AUTOSAR XML (schema 00046)
package /ComponentTypes
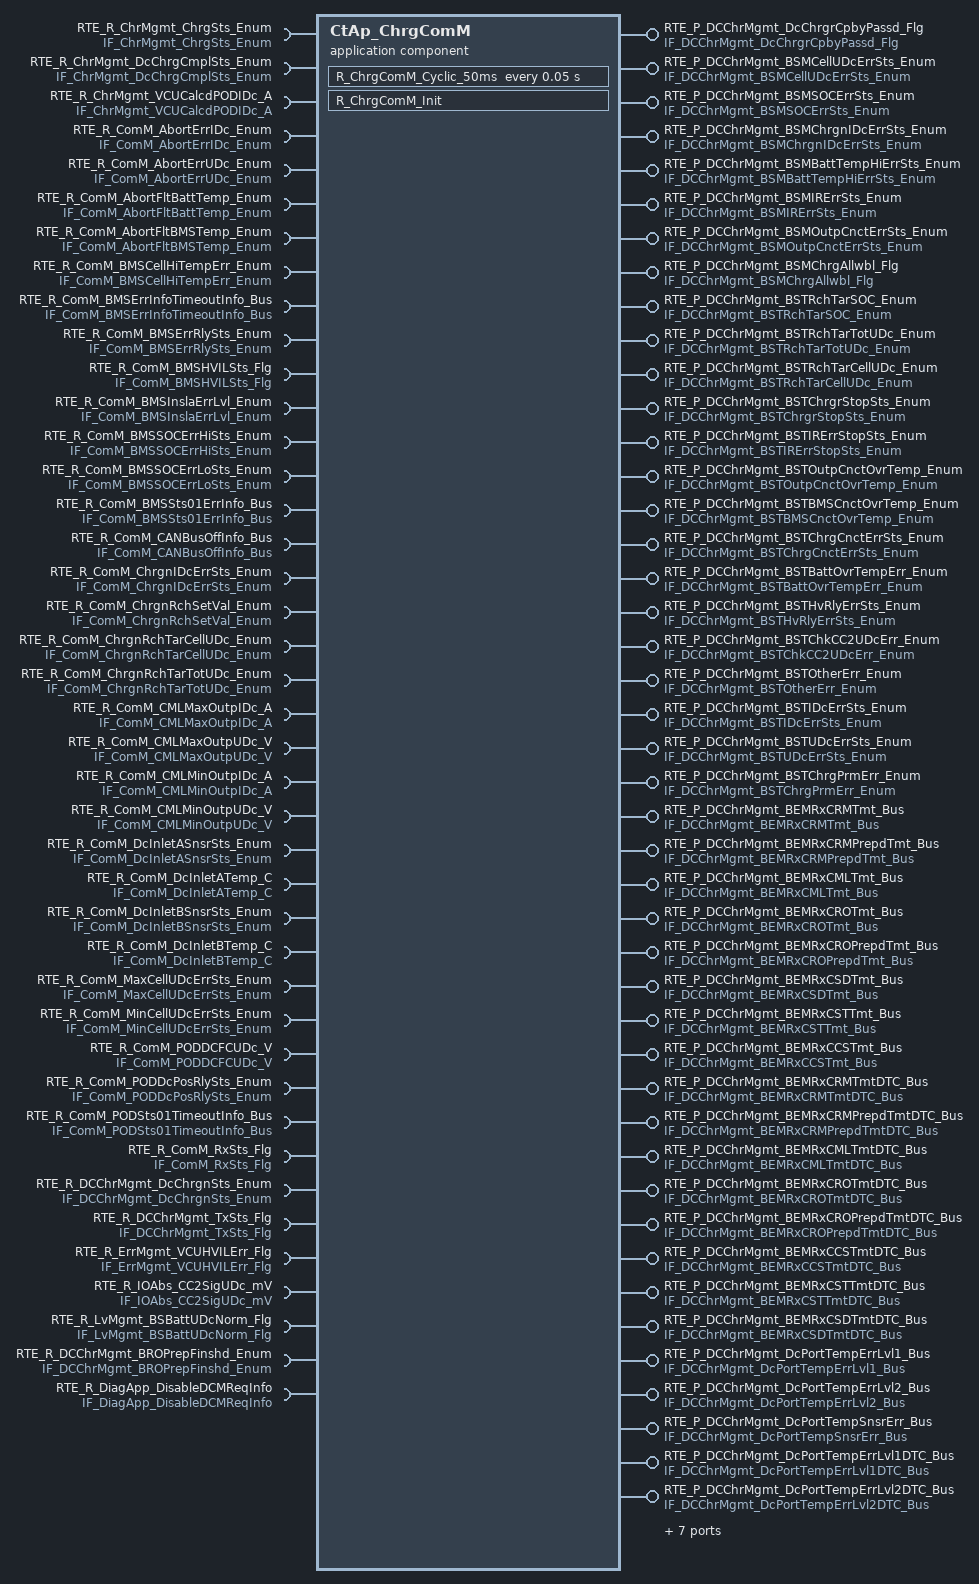
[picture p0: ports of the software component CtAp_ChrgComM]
  application sw component type CtAp_ChrgComM
    50 x provide port:
      RTE_P_DCChrMgmt_DcChrgrCpbyPassd_Flg: nonqueued-sender-com-spec{data-element=tec_DCChrMgmt_DcChrgrCpbyPassd_Flg, init-value=0}, provided-interface=IF_DCChrMgmt_DcChrgrCpbyPassd_Flg
      RTE_P_DCChrMgmt_BSMCellUDcErrSts_Enum: nonqueued-sender-com-spec{data-element=tec_DCChrMgmt_BSMCellUDcErrSts_Enum, init-value=0}, provided-interface=IF_DCChrMgmt_BSMCellUDcErrSts_Enum
      RTE_P_DCChrMgmt_BSMSOCErrSts_Enum: nonqueued-sender-com-spec{data-element=tec_DCChrMgmt_BSMSOCErrSts_Enum, init-value=0}, provided-interface=IF_DCChrMgmt_BSMSOCErrSts_Enum
      RTE_P_DCChrMgmt_BSMChrgnIDcErrSts_Enum: nonqueued-sender-com-spec{data-element=tec_DCChrMgmt_BSMChrgnIDcErrSts_Enum, init-value=0}, provided-interface=IF_DCChrMgmt_BSMChrgnIDcErrSts_Enum
      RTE_P_DCChrMgmt_BSMBattTempHiErrSts_Enum: nonqueued-sender-com-spec{data-element=tec_DCChrMgmt_BSMBattTempHiErrSts_Enum, init-value=0}, provided-interface=IF_DCChrMgmt_BSMBattTempHiErrSts_Enum
      RTE_P_DCChrMgmt_BSMIRErrSts_Enum: nonqueued-sender-com-spec{data-element=tec_DCChrMgmt_BSMIRErrSts_Enum, init-value=0}, provided-interface=IF_DCChrMgmt_BSMIRErrSts_Enum
      RTE_P_DCChrMgmt_BSMOutpCnctErrSts_Enum: nonqueued-sender-com-spec{data-element=tec_DCChrMgmt_BSMOutpCnctErrSts_Enum, init-value=0}, provided-interface=IF_DCChrMgmt_BSMOutpCnctErrSts_Enum
      RTE_P_DCChrMgmt_BSMChrgAllwbl_Flg: nonqueued-sender-com-spec{data-element=tec_DCChrMgmt_BSMChrgAllwbl_Flg, init-value=0}, provided-interface=IF_DCChrMgmt_BSMChrgAllwbl_Flg
      RTE_P_DCChrMgmt_BSTRchTarSOC_Enum: nonqueued-sender-com-spec{data-element=tec_DCChrMgmt_BSTRchTarSOC_Enum, init-value=0}, provided-interface=IF_DCChrMgmt_BSTRchTarSOC_Enum
      RTE_P_DCChrMgmt_BSTRchTarTotUDc_Enum: nonqueued-sender-com-spec{data-element=tec_DCChrMgmt_BSTRchTarTotUDc_Enum, init-value=0}, provided-interface=IF_DCChrMgmt_BSTRchTarTotUDc_Enum
      RTE_P_DCChrMgmt_BSTRchTarCellUDc_Enum: nonqueued-sender-com-spec{data-element=tec_DCChrMgmt_BSTRchTarCellUDc_Enum, init-value=0}, provided-interface=IF_DCChrMgmt_BSTRchTarCellUDc_Enum
      RTE_P_DCChrMgmt_BSTChrgrStopSts_Enum: nonqueued-sender-com-spec{data-element=tec_DCChrMgmt_BSTChrgrStopSts_Enum, init-value=0}, provided-interface=IF_DCChrMgmt_BSTChrgrStopSts_Enum
      RTE_P_DCChrMgmt_BSTIRErrStopSts_Enum: nonqueued-sender-com-spec{data-element=tec_DCChrMgmt_BSTIRErrStopSts_Enum, init-value=0}, provided-interface=IF_DCChrMgmt_BSTIRErrStopSts_Enum
      RTE_P_DCChrMgmt_BSTOutpCnctOvrTemp_Enum: nonqueued-sender-com-spec{data-element=tec_DCChrMgmt_BSTOutpCnctOvrTemp_Enum, init-value=0}, provided-interface=IF_DCChrMgmt_BSTOutpCnctOvrTemp_Enum
      RTE_P_DCChrMgmt_BSTBMSCnctOvrTemp_Enum: nonqueued-sender-com-spec{data-element=tec_DCChrMgmt_BSTBMSCnctOvrTemp_Enum, init-value=0}, provided-interface=IF_DCChrMgmt_BSTBMSCnctOvrTemp_Enum
      RTE_P_DCChrMgmt_BSTChrgCnctErrSts_Enum: nonqueued-sender-com-spec{data-element=tec_DCChrMgmt_BSTChrgCnctErrSts_Enum, init-value=0}, provided-interface=IF_DCChrMgmt_BSTChrgCnctErrSts_Enum
      RTE_P_DCChrMgmt_BSTBattOvrTempErr_Enum: nonqueued-sender-com-spec{data-element=tec_DCChrMgmt_BSTBattOvrTempErr_Enum, init-value=0}, provided-interface=IF_DCChrMgmt_BSTBattOvrTempErr_Enum
      RTE_P_DCChrMgmt_BSTHvRlyErrSts_Enum: nonqueued-sender-com-spec{data-element=tec_DCChrMgmt_BSTHvRlyErrSts_Enum, init-value=0}, provided-interface=IF_DCChrMgmt_BSTHvRlyErrSts_Enum
      RTE_P_DCChrMgmt_BSTChkCC2UDcErr_Enum: nonqueued-sender-com-spec{data-element=tec_DCChrMgmt_BSTChkCC2UDcErr_Enum, init-value=0}, provided-interface=IF_DCChrMgmt_BSTChkCC2UDcErr_Enum
      RTE_P_DCChrMgmt_BSTOtherErr_Enum: nonqueued-sender-com-spec{data-element=tec_DCChrMgmt_BSTOtherErr_Enum, init-value=0}, provided-interface=IF_DCChrMgmt_BSTOtherErr_Enum
      RTE_P_DCChrMgmt_BSTIDcErrSts_Enum: nonqueued-sender-com-spec{data-element=tec_DCChrMgmt_BSTIDcErrSts_Enum, init-value=0}, provided-interface=IF_DCChrMgmt_BSTIDcErrSts_Enum
      RTE_P_DCChrMgmt_BSTUDcErrSts_Enum: nonqueued-sender-com-spec{data-element=tec_DCChrMgmt_BSTUDcErrSts_Enum, init-value=0}, provided-interface=IF_DCChrMgmt_BSTUDcErrSts_Enum
      RTE_P_DCChrMgmt_BSTChrgPrmErr_Enum: nonqueued-sender-com-spec{data-element=tec_DCChrMgmt_BSTChrgPrmErr_Enum, init-value=0}, provided-interface=IF_DCChrMgmt_BSTChrgPrmErr_Enum
      RTE_P_DCChrMgmt_BEMRxCRMTmt_Bus: nonqueued-sender-com-spec{data-element=tec_DCChrMgmt_BEMRxCRMTmt_Bus, init-value=fields=[DCChrMgmt_MonStatBEMRxCRMTmt:0, DCChrMgmt_MonResBEMRxCRMTmt:0, DCChrMgmt_ErrStatBEMRxCRMTmt:0, DCChrMgmt_ErrResBEMRxCRMTmt:0]}, provided-interface=IF_DCChrMgmt_BEMRxCRMTmt_Bus
      RTE_P_DCChrMgmt_BEMRxCRMPrepdTmt_Bus: nonqueued-sender-com-spec{data-element=tec_DCChrMgmt_BEMRxCRMPrepdTmt_Bus, init-value=fields=[DCChrMgmt_MonStatBEMRxCRMPrepdTmt:0, DCChrMgmt_MonResBEMRxCRMPrepdTmt:0, DCChrMgmt_ErrStatBEMRxCRMPrepdTmt:0, DCChrMgmt_ErrResBEMRxCRMPrepdTmt:0]}, provided-interface=IF_DCChrMgmt_BEMRxCRMPrepdTmt_Bus
      RTE_P_DCChrMgmt_BEMRxCMLTmt_Bus: nonqueued-sender-com-spec{data-element=tec_DCChrMgmt_BEMRxCMLTmt_Bus, init-value=fields=[DCChrMgmt_MonStatBEMRxCMLTmt:0, DCChrMgmt_MonResBEMRxCMLTmt:0, DCChrMgmt_ErrStatBEMRxCMLTmt:0, DCChrMgmt_ErrResBEMRxCMLTmt:0]}, provided-interface=IF_DCChrMgmt_BEMRxCMLTmt_Bus
      RTE_P_DCChrMgmt_BEMRxCROTmt_Bus: nonqueued-sender-com-spec{data-element=tec_DCChrMgmt_BEMRxCROTmt_Bus, init-value=fields=[DCChrMgmt_MonStatBEMRxCROTmt:0, DCChrMgmt_MonResBEMRxCROTmt:0, DCChrMgmt_ErrStatBEMRxCROTmt:0, DCChrMgmt_ErrResBEMRxCROTmt:0]}, provided-interface=IF_DCChrMgmt_BEMRxCROTmt_Bus
      RTE_P_DCChrMgmt_BEMRxCROPrepdTmt_Bus: nonqueued-sender-com-spec{data-element=tec_DCChrMgmt_BEMRxCROPrepdTmt_Bus, init-value=fields=[DCChrMgmt_MonStatBEMRxCROPrepdTmt:0, DCChrMgmt_MonResBEMRxCROPrepdTmt:0, DCChrMgmt_ErrStatBEMRxCROPrepdTmt:0, DCChrMgmt_ErrResBEMRxCROPrepdTmt:0]}, provided-interface=IF_DCChrMgmt_BEMRxCROPrepdTmt_Bus
      RTE_P_DCChrMgmt_BEMRxCSDTmt_Bus: nonqueued-sender-com-spec{data-element=tec_DCChrMgmt_BEMRxCSDTmt_Bus, init-value=fields=[DCChrMgmt_MonStatBEMRxCSDTmt:0, DCChrMgmt_MonResBEMRxCSDTmt:0, DCChrMgmt_ErrStatBEMRxCSDTmt:0, DCChrMgmt_ErrResBEMRxCSDTmt:0]}, provided-interface=IF_DCChrMgmt_BEMRxCSDTmt_Bus
      RTE_P_DCChrMgmt_BEMRxCSTTmt_Bus: nonqueued-sender-com-spec{data-element=tec_DCChrMgmt_BEMRxCSTTmt_Bus, init-value=fields=[DCChrMgmt_MonStatBEMRxCSTTmt:0, DCChrMgmt_MonResBEMRxCSTTmt:0, DCChrMgmt_ErrStatBEMRxCSTTmt:0, DCChrMgmt_ErrResBEMRxCSTTmt:0]}, provided-interface=IF_DCChrMgmt_BEMRxCSTTmt_Bus
      RTE_P_DCChrMgmt_BEMRxCCSTmt_Bus: nonqueued-sender-com-spec{data-element=tec_DCChrMgmt_BEMRxCCSTmt_Bus, init-value=fields=[DCChrMgmt_MonStatBEMRxCCSTmt:0, DCChrMgmt_MonResBEMRxCCSTmt:0, DCChrMgmt_ErrStatBEMRxCCSTmt:0, DCChrMgmt_ErrResBEMRxCCSTmt:0]}, provided-interface=IF_DCChrMgmt_BEMRxCCSTmt_Bus
      RTE_P_DCChrMgmt_BEMRxCRMTmtDTC_Bus: nonqueued-sender-com-spec{data-element=tec_DCChrMgmt_BEMRxCRMTmtDTC_Bus, init-value=fields=[DCChrMgmt_MonStatBEMRxCRMTmtDTC:0, DCChrMgmt_MonResBEMRxCRMTmtDTC:0, DCChrMgmt_ErrStatBEMRxCRMTmtDTC:0, DCChrMgmt_ErrResBEMRxCRMTmtDTC:0]}, provided-interface=IF_DCChrMgmt_BEMRxCRMTmtDTC_Bus
      RTE_P_DCChrMgmt_BEMRxCRMPrepdTmtDTC_Bus: nonqueued-sender-com-spec{data-element=tec_DCChrMgmt_BEMRxCRMPrepdTmtDTC_Bus, init-value=fields=[DCChrMgmt_MonStatBEMRxCRMPrepdTmtDTC:0, DCChrMgmt_MonResBEMRxCRMPrepdTmtDTC:0, DCChrMgmt_ErrStatBEMRxCRMPrepdTmtDTC:0, DCChrMgmt_ErrResBEMRxCRMPrepdTmtDTC:0]}, provided-interface=IF_DCChrMgmt_BEMRxCRMPrepdTmtDTC_Bus
      RTE_P_DCChrMgmt_BEMRxCMLTmtDTC_Bus: nonqueued-sender-com-spec{data-element=tec_DCChrMgmt_BEMRxCMLTmtDTC_Bus, init-value=fields=[DCChrMgmt_MonStatBEMRxCMLTmtDTC:0, DCChrMgmt_MonResBEMRxCMLTmtDTC:0, DCChrMgmt_ErrStatBEMRxCMLTmtDTC:0, DCChrMgmt_ErrResBEMRxCMLTmtDTC:0]}, provided-interface=IF_DCChrMgmt_BEMRxCMLTmtDTC_Bus
      RTE_P_DCChrMgmt_BEMRxCROTmtDTC_Bus: nonqueued-sender-com-spec{data-element=tec_DCChrMgmt_BEMRxCROTmtDTC_Bus, init-value=fields=[DCChrMgmt_MonStatBEMRxCROTmtDTC:0, DCChrMgmt_MonResBEMRxCROTmtDTC:0, DCChrMgmt_ErrStatBEMRxCROTmtDTC:0, DCChrMgmt_ErrResBEMRxCROTmtDTC:0]}, provided-interface=IF_DCChrMgmt_BEMRxCROTmtDTC_Bus
      RTE_P_DCChrMgmt_BEMRxCROPrepdTmtDTC_Bus: nonqueued-sender-com-spec{data-element=tec_DCChrMgmt_BEMRxCROPrepdTmtDTC_Bus, init-value=fields=[DCChrMgmt_MonStatBEMRxCROPrepdTmtDTC:0, DCChrMgmt_MonResBEMRxCROPrepdTmtDTC:0, DCChrMgmt_ErrStatBEMRxCROPrepdTmtDTC:0, DCChrMgmt_ErrResBEMRxCROPrepdTmtDTC:0]}, provided-interface=IF_DCChrMgmt_BEMRxCROPrepdTmtDTC_Bus
      RTE_P_DCChrMgmt_BEMRxCCSTmtDTC_Bus: nonqueued-sender-com-spec{data-element=tec_DCChrMgmt_BEMRxCCSTmtDTC_Bus, init-value=fields=[DCChrMgmt_MonStatBEMRxCCSTmtDTC:0, DCChrMgmt_MonResBEMRxCCSTmtDTC:0, DCChrMgmt_ErrStatBEMRxCCSTmtDTC:0, DCChrMgmt_ErrResBEMRxCCSTmtDTC:0]}, provided-interface=IF_DCChrMgmt_BEMRxCCSTmtDTC_Bus
      RTE_P_DCChrMgmt_BEMRxCSTTmtDTC_Bus: nonqueued-sender-com-spec{data-element=tec_DCChrMgmt_BEMRxCSTTmtDTC_Bus, init-value=fields=[DCChrMgmt_MonStatBEMRxCSTTmtDTC:0, DCChrMgmt_MonResBEMRxCSTTmtDTC:0, DCChrMgmt_ErrStatBEMRxCSTTmtDTC:0, DCChrMgmt_ErrResBEMRxCSTTmtDTC:0]}, provided-interface=IF_DCChrMgmt_BEMRxCSTTmtDTC_Bus
      RTE_P_DCChrMgmt_BEMRxCSDTmtDTC_Bus: nonqueued-sender-com-spec{data-element=tec_DCChrMgmt_BEMRxCSDTmtDTC_Bus, init-value=fields=[DCChrMgmt_MonStatBEMRxCSDTmtDTC:0, DCChrMgmt_MonResBEMRxCSDTmtDTC:0, DCChrMgmt_ErrStatBEMRxCSDTmtDTC:0, DCChrMgmt_ErrResBEMRxCSDTmtDTC:0]}, provided-interface=IF_DCChrMgmt_BEMRxCSDTmtDTC_Bus
      RTE_P_DCChrMgmt_DcPortTempErrLvl1_Bus: nonqueued-sender-com-spec{data-element=tec_DCChrMgmt_DcPortTempErrLvl1_Bus, init-value=fields=[DCChrMgmt_MonStatDcPortTempErrLvl1:0, DCChrMgmt_MonResDcPortTempErrLvl1:0, DCChrMgmt_ErrStatDcPortTempErrLvl1:0, DCChrMgmt_ErrResDcPortTempErrLvl1:0]}, provided-interface=IF_DCChrMgmt_DcPortTempErrLvl1_Bus
      RTE_P_DCChrMgmt_DcPortTempErrLvl2_Bus: nonqueued-sender-com-spec{data-element=tec_DCChrMgmt_DcPortTempErrLvl2_Bus, init-value=fields=[DCChrMgmt_MonStatDcPortTempErrLvl2:0, DCChrMgmt_MonResDcPortTempErrLvl2:0, DCChrMgmt_ErrStatDcPortTempErrLvl2:0, DCChrMgmt_ErrResDcPortTempErrLvl2:0]}, provided-interface=IF_DCChrMgmt_DcPortTempErrLvl2_Bus
      RTE_P_DCChrMgmt_DcPortTempSnsrErr_Bus: nonqueued-sender-com-spec{data-element=tec_DCChrMgmt_DcPortTempSnsrErr_Bus, init-value=fields=[DCChrMgmt_MonStatDcPortTempSnsrErr:0, DCChrMgmt_MonResDcPortTempSnsrErr:0, DCChrMgmt_ErrStatDcPortTempSnsrErr:0, DCChrMgmt_ErrResDcPortTempSnsrErr:0]}, provided-interface=IF_DCChrMgmt_DcPortTempSnsrErr_Bus
      RTE_P_DCChrMgmt_DcPortTempErrLvl1DTC_Bus: nonqueued-sender-com-spec{data-element=tec_DCChrMgmt_DcPortTempErrLvl1DTC_Bus, init-value=fields=[DCChrMgmt_MonStatDcPortTempErrLvl1DTC:0, DCChrMgmt_MonResDcPortTempErrLvl1DTC:0, DCChrMgmt_ErrStatDcPortTempErrLvl1DTC:0, DCChrMgmt_ErrResDcPortTempErrLvl1DTC:0]}, provided-interface=IF_DCChrMgmt_DcPortTempErrLvl1DTC_Bus
      RTE_P_DCChrMgmt_DcPortTempErrLvl2DTC_Bus: nonqueued-sender-com-spec{data-element=tec_DCChrMgmt_DcPortTempErrLvl2DTC_Bus, init-value=fields=[DCChrMgmt_MonStatDcPortTempErrLvl2DTC:0, DCChrMgmt_MonResDcPortTempErrLvl2DTC:0, DCChrMgmt_ErrStatDcPortTempErrLvl2DTC:0, DCChrMgmt_ErrResDcPortTempErrLvl2DTC:0]}, provided-interface=IF_DCChrMgmt_DcPortTempErrLvl2DTC_Bus
      RTE_P_DCChrMgmt_DcPortTempSnsrErrDTC_Bus: nonqueued-sender-com-spec{data-element=tec_DCChrMgmt_DcPortTempSnsrErrDTC_Bus, init-value=fields=[DCChrMgmt_MonStatDcPortTempSnsrErrDTC:0, DCChrMgmt_MonResDcPortTempSnsrErrDTC:0, DCChrMgmt_ErrStatDcPortTempSnsrErrDTC:0, DCChrMgmt_ErrResDcPortTempSnsrErrDTC:0]}, provided-interface=IF_DCChrMgmt_DcPortTempSnsrErrDTC_Bus
      RTE_P_DCChrMgmt_MaxChrgUDc_V: nonqueued-sender-com-spec{data-element=tec_DCChrMgmt_MaxChrgUDc_V, init-value=0}, provided-interface=IF_DCChrMgmt_MaxChrgUDc_V
      RTE_P_DCChrMgmt_MinChrgUDc_V: nonqueued-sender-com-spec{data-element=tec_DCChrMgmt_MinChrgUDc_V, init-value=0}, provided-interface=IF_DCChrMgmt_MinChrgUDc_V
      RTE_P_DCChrMgmt_MaxChrgIDc_A: nonqueued-sender-com-spec{data-element=tec_DCChrMgmt_MaxChrgIDc_A, init-value=0}, provided-interface=IF_DCChrMgmt_MaxChrgIDc_A
      RTE_P_DCChrMgmt_MinChrgIDc_A: nonqueued-sender-com-spec{data-element=tec_DCChrMgmt_MinChrgIDc_A, init-value=0}, provided-interface=IF_DCChrMgmt_MinChrgIDc_A
      RTE_P_DCChrMgmt_BEMTxReqSts_Enum: nonqueued-sender-com-spec{data-element=tec_DCChrMgmt_BEMTxReqSts_Enum, init-value=0}, provided-interface=IF_DCChrMgmt_BEMTxReqSts_Enum
    41 x require port:
      RTE_R_ChrMgmt_ChrgSts_Enum: nonqueued-receiver-com-spec{data-element=tec_ChrMgmt_ChrgSts_Enum, filter=data-filter-type=ALWAYS, init-value=0}, required-interface=IF_ChrMgmt_ChrgSts_Enum
      RTE_R_ChrMgmt_DcChrgCmplSts_Enum: nonqueued-receiver-com-spec{data-element=tec_ChrMgmt_DcChrgCmplSts_Enum, filter=data-filter-type=ALWAYS, init-value=0}, required-interface=IF_ChrMgmt_DcChrgCmplSts_Enum
      RTE_R_ChrMgmt_VCUCalcdPODIDc_A: nonqueued-receiver-com-spec{data-element=tec_ChrMgmt_VCUCalcdPODIDc_A, filter=data-filter-type=ALWAYS, init-value=0}, required-interface=IF_ChrMgmt_VCUCalcdPODIDc_A
      RTE_R_ComM_AbortErrIDc_Enum: nonqueued-receiver-com-spec{data-element=tec_ComM_AbortErrIDc_Enum, filter=data-filter-type=ALWAYS, init-value=0}, required-interface=IF_ComM_AbortErrIDc_Enum
      RTE_R_ComM_AbortErrUDc_Enum: nonqueued-receiver-com-spec{data-element=tec_ComM_AbortErrUDc_Enum, filter=data-filter-type=ALWAYS, init-value=0}, required-interface=IF_ComM_AbortErrUDc_Enum
      RTE_R_ComM_AbortFltBattTemp_Enum: nonqueued-receiver-com-spec{data-element=tec_ComM_AbortFltBattTemp_Enum, filter=data-filter-type=ALWAYS, init-value=0}, required-interface=IF_ComM_AbortFltBattTemp_Enum
      RTE_R_ComM_AbortFltBMSTemp_Enum: nonqueued-receiver-com-spec{data-element=tec_ComM_AbortFltBMSTemp_Enum, filter=data-filter-type=ALWAYS, init-value=0}, required-interface=IF_ComM_AbortFltBMSTemp_Enum
      RTE_R_ComM_BMSCellHiTempErr_Enum: nonqueued-receiver-com-spec{data-element=tec_ComM_BMSCellHiTempErr_Enum, filter=data-filter-type=ALWAYS, init-value=0}, required-interface=IF_ComM_BMSCellHiTempErr_Enum
      RTE_R_ComM_BMSErrInfoTimeoutInfo_Bus: nonqueued-receiver-com-spec{data-element=tec_ComM_BMSErrInfoTimeoutInfo_Bus, filter=data-filter-type=ALWAYS, init-value=fields=[ComM_MonStatBMSErrInfoTimeoutInfo:0, ComM_MonResBMSErrInfoTimeoutInfo:0, ComM_ErrStatBMSErrInfoTimeoutInfo:0, ComM_ErrResBMSErrInfoTimeoutInfo:0]}, required-interface=IF_ComM_BMSErrInfoTimeoutInfo_Bus
      RTE_R_ComM_BMSErrRlySts_Enum: nonqueued-receiver-com-spec{data-element=tec_ComM_BMSErrRlySts_Enum, filter=data-filter-type=ALWAYS, init-value=0}, required-interface=IF_ComM_BMSErrRlySts_Enum
      RTE_R_ComM_BMSHVILSts_Flg: nonqueued-receiver-com-spec{data-element=tec_ComM_BMSHVILSts_Flg, filter=data-filter-type=ALWAYS, init-value=0}, required-interface=IF_ComM_BMSHVILSts_Flg
      RTE_R_ComM_BMSInslaErrLvl_Enum: nonqueued-receiver-com-spec{data-element=tec_ComM_BMSInslaErrLvl_Enum, filter=data-filter-type=ALWAYS, init-value=0}, required-interface=IF_ComM_BMSInslaErrLvl_Enum
      RTE_R_ComM_BMSSOCErrHiSts_Enum: nonqueued-receiver-com-spec{data-element=tec_ComM_BMSSOCHiErrSts_Enum, filter=data-filter-type=ALWAYS, init-value=0}, required-interface=IF_ComM_BMSSOCErrHiSts_Enum
      RTE_R_ComM_BMSSOCErrLoSts_Enum: nonqueued-receiver-com-spec{data-element=tec_ComM_BMSSOCLoErrSts_Enum, filter=data-filter-type=ALWAYS, init-value=0}, required-interface=IF_ComM_BMSSOCErrLoSts_Enum
      RTE_R_ComM_BMSSts01ErrInfo_Bus: required-interface=IF_ComM_BMSSts01ErrInfo_Bus
        required-com-specs:
          data-element=tec_ComM_BMSSts01TimeoutInfo_Bus, filter=data-filter-type=ALWAYS, init-value=fields=[ComM_MonStatBMSSts01TimeoutInfo:0, ComM_MonResBMSSts01TimeoutInfo:0, ComM_ErrStatBMSSts01TimeoutInfo:0, ComM_ErrResBMSSts01TimeoutInfo:0]
          data-element=tec_ComM_BMSSts01CRCDTCInfo_Bus, filter=data-filter-type=ALWAYS, init-value=fields=[ComM_MonStatBMSSts01CRCDTCErrorInfo:0, ComM_MonResBMSSts01CRCDTCErrorInfo:0, ComM_ErrStatBMSSts01CRCDTCErrorInfo:0, ComM_ErrResBMSSts01CRCDTCErrorInfo:0]
          data-element=tec_ComM_BMSSts01CRCInfo_Bus, filter=data-filter-type=ALWAYS, init-value=fields=[ComM_MonStatBMSSts01CRCErrorInfo:0, ComM_MonResBMSSts01CRCErrorInfo:0, ComM_ErrStatBMSSts01CRCErrorInfo:0, ComM_ErrResBMSSts01CRCErrorInfo:0]
          data-element=tec_ComM_BMSSts01TimeoutDTCInfo_Bus, filter=data-filter-type=ALWAYS, init-value=fields=[ComM_MonStatBMSSts01TimeoutDTCErrorInfo:0, ComM_MonResBMSSts01TimeoutDTCErrorInfo:0, ComM_ErrStatBMSSts01TimeoutDTCErrorInfo:0, ComM_ErrResBMSSts01TimeoutDTCErrorInfo:0]
          data-element=tec_ComM_BMSSts01E2ETimeoutInfo_Bus, filter=data-filter-type=ALWAYS, init-value=fields=[ComM_MonStatBMSSts01E2ETimeoutInfo:0, ComM_MonResBMSSts01E2ETimeoutInfo:0, ComM_ErrStatBMSSts01E2ETimeoutInfo:0, ComM_ErrResBMSSts01E2ETimeoutInfo:0]
      RTE_R_ComM_CANBusOffInfo_Bus: required-interface=IF_ComM_CANBusOffInfo_Bus
        required-com-specs:
          data-element=tec_ComM_EPTCANBusOffInfo_Bus, filter=data-filter-type=ALWAYS, init-value=fields=[ComM_MonStatEPTCANBusOffInfo:0, ComM_MonResEPTCANBusOffInfo:0, ComM_ErrStatEPTCANBusOffInfo:0, ComM_ErrResEPTCANBusOffInfo:0]
          data-element=tec_ComM_CHCANBusOffInfo_Bus, filter=data-filter-type=ALWAYS, init-value=fields=[ComM_MonStatCHCANBusOffInfo:0, ComM_MonResCHCANBusOffInfo:0, ComM_ErrStatCHCANBusOffInfo:0, ComM_ErrResCHCANBusOffInfo:0]
          data-element=tec_ComM_EPTCANBusOffDTCInfo_Bus, filter=data-filter-type=ALWAYS, init-value=fields=[ComM_MonStatEPTCANBusOffDTCInfo:0, ComM_MonResEPTCANBusOffDTCInfo:0, ComM_ErrStatEPTCANBusOffDTCInfo:0, ComM_ErrResEPTCANBusOffDTCInfo:0]
          data-element=tec_ComM_CHCANBusOffDTCInfo_Bus, filter=data-filter-type=ALWAYS, init-value=fields=[ComM_MonStatCHCANBusOffDTCInfo:0, ComM_MonResCHCANBusOffDTCInfo:0, ComM_ErrStatCHCANBusOffDTCInfo:0, ComM_ErrResCHCANBusOffDTCInfo:0]
          data-element=tec_ComM_DCCANBusOffDTCInfo_Bus, filter=data-filter-type=ALWAYS, init-value=fields=[ComM_MonStatDCCANDTCBusOffInfo:0, ComM_MonResDCCANDTCBusOffInfo:0, ComM_ErrStatDCCANDTCBusOffInfo:0, ComM_ErrResDCCANDTCBusOffInfo:0]
          data-element=tec_ComM_DCCANBusOffInfo_Bus, filter=data-filter-type=ALWAYS, init-value=fields=[ComM_MonStatDCCANBusOffInfo:0, ComM_MonResDCCANBusOffInfo:0, ComM_ErrStatDCCANBusOffInfo:0, ComM_ErrResDCCANBusOffInfo:0]
      RTE_R_ComM_ChrgnIDcErrSts_Enum: nonqueued-receiver-com-spec{data-element=tec_ComM_ChrgnIDcErrSts_Enum, filter=data-filter-type=ALWAYS, init-value=0}, required-interface=IF_ComM_ChrgnIDcErrSts_Enum
      RTE_R_ComM_ChrgnRchSetVal_Enum: nonqueued-receiver-com-spec{data-element=tec_ComM_ChrgnRchSetVal_Enum, filter=data-filter-type=ALWAYS, init-value=0}, required-interface=IF_ComM_ChrgnRchSetVal_Enum
      RTE_R_ComM_ChrgnRchTarCellUDc_Enum: nonqueued-receiver-com-spec{data-element=tec_ComM_ChrgnRchTarCellUDc_Enum, filter=data-filter-type=ALWAYS, init-value=0}, required-interface=IF_ComM_ChrgnRchTarCellUDc_Enum
      RTE_R_ComM_ChrgnRchTarTotUDc_Enum: nonqueued-receiver-com-spec{data-element=tec_ComM_ChrgnRchTarTotUDc_Enum, filter=data-filter-type=ALWAYS, init-value=0}, required-interface=IF_ComM_ChrgnRchTarTotUDc_Enum
      RTE_R_ComM_CMLMaxOutpIDc_A: nonqueued-receiver-com-spec{data-element=tec_ComM_CMLMaxOutpIDc_A, filter=data-filter-type=ALWAYS, init-value=0}, required-interface=IF_ComM_CMLMaxOutpIDc_A
      RTE_R_ComM_CMLMaxOutpUDc_V: nonqueued-receiver-com-spec{data-element=tec_ComM_CMLMaxOutpUDc_V, filter=data-filter-type=ALWAYS, init-value=0}, required-interface=IF_ComM_CMLMaxOutpUDc_V
      RTE_R_ComM_CMLMinOutpIDc_A: nonqueued-receiver-com-spec{data-element=tec_ComM_CMLMinOutpIDc_A, filter=data-filter-type=ALWAYS, init-value=0}, required-interface=IF_ComM_CMLMinOutpIDc_A
      RTE_R_ComM_CMLMinOutpUDc_V: nonqueued-receiver-com-spec{data-element=tec_ComM_CMLMinOutpUDc_V, filter=data-filter-type=ALWAYS, init-value=0}, required-interface=IF_ComM_CMLMinOutpUDc_V
      RTE_R_ComM_DcInletASnsrSts_Enum: nonqueued-receiver-com-spec{data-element=tec_ComM_DcInletASnsrSts_Enum, filter=data-filter-type=ALWAYS, init-value=0}, required-interface=IF_ComM_DcInletASnsrSts_Enum
      RTE_R_ComM_DcInletATemp_C: nonqueued-receiver-com-spec{data-element=tec_ComM_DcInletATemp_C, filter=data-filter-type=ALWAYS, init-value=0}, required-interface=IF_ComM_DcInletATemp_C
      RTE_R_ComM_DcInletBSnsrSts_Enum: nonqueued-receiver-com-spec{data-element=tec_ComM_DcInletBSnsrSts_Enum, filter=data-filter-type=ALWAYS, init-value=0}, required-interface=IF_ComM_DcInletBSnsrSts_Enum
      RTE_R_ComM_DcInletBTemp_C: nonqueued-receiver-com-spec{data-element=tec_ComM_DcInletBTemp_C, filter=data-filter-type=ALWAYS, init-value=0}, required-interface=IF_ComM_DcInletBTemp_C
      RTE_R_ComM_MaxCellUDcErrSts_Enum: nonqueued-receiver-com-spec{data-element=tec_ComM_MaxCellUDcErrSts_Enum, filter=data-filter-type=ALWAYS, init-value=0}, required-interface=IF_ComM_MaxCellUDcErrSts_Enum
      RTE_R_ComM_MinCellUDcErrSts_Enum: nonqueued-receiver-com-spec{data-element=tec_ComM_MinCellUDcErrSts_Enum, filter=data-filter-type=ALWAYS, init-value=0}, required-interface=IF_ComM_MinCellUDcErrSts_Enum
      RTE_R_ComM_PODDCFCUDc_V: nonqueued-receiver-com-spec{data-element=tec_ComM_PODDCFCUDc_V, filter=data-filter-type=ALWAYS, init-value=0}, required-interface=IF_ComM_PODDCFCUDc_V
      RTE_R_ComM_PODDcPosRlySts_Enum: nonqueued-receiver-com-spec{data-element=tec_ComM_PODDcPosRlySts_Enum, filter=data-filter-type=ALWAYS, init-value=0}, required-interface=IF_ComM_PODDcPosRlySts_Enum
      RTE_R_ComM_PODSts01TimeoutInfo_Bus: nonqueued-receiver-com-spec{data-element=tec_ComM_PODSts01TimeoutInfo_Bus, filter=data-filter-type=ALWAYS, init-value=fields=[ComM_MonStatPODSts01TimeoutInfo:0, ComM_MonResPODSts01TimeoutInfo:0, ComM_ErrStatPODSts01TimeoutInfo:0, ComM_ErrResPODSts01TimeoutInfo:0]}, required-interface=IF_ComM_PODSts01TimeoutInfo_Bus
      RTE_R_ComM_RxSts_Flg: required-interface=IF_ComM_RxSts_Flg
        required-com-specs:
          data-element=tec_ComM_RxCROSts_Flg, filter=data-filter-type=ALWAYS, init-value=0
          data-element=tec_ComM_RxCEMSts_Flg, filter=data-filter-type=ALWAYS, init-value=0
          data-element=tec_ComM_RxCHMSts_Flg, filter=data-filter-type=ALWAYS, init-value=0
          data-element=tec_ComM_RxCSTSts_Flg, filter=data-filter-type=ALWAYS, init-value=0
          data-element=tec_ComM_RxCSDSts_Flg, filter=data-filter-type=ALWAYS, init-value=0
          data-element=tec_ComM_RxCCSSts_Flg, filter=data-filter-type=ALWAYS, init-value=0
          data-element=tec_ComM_RxCMLSts_Flg, filter=data-filter-type=ALWAYS, init-value=0
          data-element=tec_ComM_RxCRMSts_Flg, filter=data-filter-type=ALWAYS, init-value=0
      RTE_R_DCChrMgmt_DcChrgnSts_Enum: nonqueued-receiver-com-spec{data-element=tec_DCChrMgmt_DcChrgnSts_Enum, filter=data-filter-type=ALWAYS, init-value=0}, required-interface=IF_DCChrMgmt_DcChrgnSts_Enum
      RTE_R_DCChrMgmt_TxSts_Flg: required-interface=IF_DCChrMgmt_TxSts_Flg
        required-com-specs:
          data-element=tec_DCChrMgmt_TxBSDSts_Flg, filter=data-filter-type=ALWAYS, init-value=0
          data-element=tec_DCChrMgmt_TxBEMSts_Flg, filter=data-filter-type=ALWAYS, init-value=0
          data-element=tec_DCChrMgmt_TxBSMSts_Flg, filter=data-filter-type=ALWAYS, init-value=0
          data-element=tec_DCChrMgmt_TxBCSSts_Flg, filter=data-filter-type=ALWAYS, init-value=0
          data-element=tec_DCChrMgmt_TxBSTSts_Flg, filter=data-filter-type=ALWAYS, init-value=0
          data-element=tec_DCChrMgmt_TxBCLSts_Flg, filter=data-filter-type=ALWAYS, init-value=0
          data-element=tec_DCChrMgmt_TxBROSts_Flg, filter=data-filter-type=ALWAYS, init-value=0
          data-element=tec_DCChrMgmt_TxBCPSts_Flg, filter=data-filter-type=ALWAYS, init-value=0
          data-element=tec_DCChrMgmt_TxBRMSts_Flg, filter=data-filter-type=ALWAYS, init-value=0
          data-element=tec_DCChrMgmt_TxBHMSts_Flg, filter=data-filter-type=ALWAYS, init-value=0
      RTE_R_ErrMgmt_VCUHVILErr_Flg: nonqueued-receiver-com-spec{data-element=tec_ErrMgmt_VCUHVILErr_Flg, filter=data-filter-type=ALWAYS, init-value=0}, required-interface=IF_ErrMgmt_VCUHVILErr_Flg
      RTE_R_IOAbs_CC2SigUDc_mV: nonqueued-receiver-com-spec{data-element=tec_IOAbs_CC2SigUDc_mV, filter=data-filter-type=ALWAYS, init-value=0}, required-interface=IF_IOAbs_CC2SigUDc_mV
      RTE_R_LvMgmt_BSBattUDcNorm_Flg: nonqueued-receiver-com-spec{data-element=tec_LvMgmt_BSBattUDcNorm_Flg, filter=data-filter-type=ALWAYS, init-value=0}, required-interface=IF_LvMgmt_BSBattUDcNorm_Flg
      RTE_R_DCChrMgmt_BROPrepFinshd_Enum: nonqueued-receiver-com-spec{data-element=tec_DCChrMgmt_BROPrepFinshd_Enum, filter=data-filter-type=ALWAYS, init-value=0}, required-interface=IF_DCChrMgmt_BROPrepFinshd_Enum
      RTE_R_DiagApp_DisableDCMReqInfo: nonqueued-receiver-com-spec{data-element=tec_DiagApp_DisableDCMReqInfo, filter=data-filter-type=ALWAYS, init-value=0}, required-interface=IF_DiagApp_DisableDCMReqInfo
    provide port RTE_P_DCChrMgmt_BSTTxReqSts: nonqueued-sender-com-spec{data-element=tec_DCChrMgmt_BSTTxReqSts, init-value=0}, provided-interface=IF_DCChrMgmt_BSTTxReqSts
    behavior CtAp_ChrgComM_InternalBehavior
      timing event TMT_R_ChrgComM_Cyclic_50ms: start-on-event=R_ChrgComM_Cyclic_50ms, period=0.05
      init event CtAp_ChrgComM_InitEvent: start-on-event=R_ChrgComM_Init
      runnable R_ChrgComM_Cyclic_50ms
        data-receive-point-by-arguments:
          58 x access:
            REC_RTE_R_ChrMgmt_ChrgSts_Enum_tec_ChrMgmt_ChrgSts_Enum: accessed-variable=RTE_R_ChrMgmt_ChrgSts_Enum.tec_ChrMgmt_ChrgSts_Enum
            REC_RTE_R_ChrMgmt_DcChrgCmplSts_Enum_tec_ChrMgmt_DcChrgCmplSts_Enum: accessed-variable=RTE_R_ChrMgmt_DcChrgCmplSts_Enum.tec_ChrMgmt_DcChrgCmplSts_Enum
            REC_RTE_R_ChrMgmt_VCUCalcdPODIDc_A_tec_ChrMgmt_VCUCalcdPODIDc_A: accessed-variable=RTE_R_ChrMgmt_VCUCalcdPODIDc_A.tec_ChrMgmt_VCUCalcdPODIDc_A
            REC_RTE_R_ComM_AbortErrIDc_Enum_tec_ComM_AbortErrIDc_Enum: accessed-variable=RTE_R_ComM_AbortErrIDc_Enum.tec_ComM_AbortErrIDc_Enum
            REC_RTE_R_ComM_AbortErrUDc_Enum_tec_ComM_AbortErrUDc_Enum: accessed-variable=RTE_R_ComM_AbortErrUDc_Enum.tec_ComM_AbortErrUDc_Enum
            REC_RTE_R_ComM_AbortFltBMSTemp_Enum_tec_ComM_AbortFltBMSTemp_Enum: accessed-variable=RTE_R_ComM_AbortFltBMSTemp_Enum.tec_ComM_AbortFltBMSTemp_Enum
            REC_RTE_R_ComM_AbortFltBattTemp_Enum_tec_ComM_AbortFltBattTemp_Enum: accessed-variable=RTE_R_ComM_AbortFltBattTemp_Enum.tec_ComM_AbortFltBattTemp_Enum
            REC_RTE_R_ComM_BMSCellHiTempErr_Enum_tec_ComM_BMSCellHiTempErr_Enum: accessed-variable=RTE_R_ComM_BMSCellHiTempErr_Enum.tec_ComM_BMSCellHiTempErr_Enum
            REC_RTE_R_ComM_BMSErrInfoTimeoutInfo_Bus_tec_ComM_BMSErrInfoTimeoutInfo_Bus: accessed-variable=RTE_R_ComM_BMSErrInfoTimeoutInfo_Bus.tec_ComM_BMSErrInfoTimeoutInfo_Bus
            REC_RTE_R_ComM_BMSErrRlySts_Enum_tec_ComM_BMSErrRlySts_Enum: accessed-variable=RTE_R_ComM_BMSErrRlySts_Enum.tec_ComM_BMSErrRlySts_Enum
            REC_RTE_R_ComM_BMSHVILSts_Flg_tec_ComM_BMSHVILSts_Flg: accessed-variable=RTE_R_ComM_BMSHVILSts_Flg.tec_ComM_BMSHVILSts_Flg
            REC_RTE_R_ComM_BMSInslaErrLvl_Enum_tec_ComM_BMSInslaErrLvl_Enum: accessed-variable=RTE_R_ComM_BMSInslaErrLvl_Enum.tec_ComM_BMSInslaErrLvl_Enum
            REC_RTE_R_ComM_BMSSOCErrHiSts_Enum_tec_ComM_BMSSOCHiErrSts_Enum: accessed-variable=RTE_R_ComM_BMSSOCErrHiSts_Enum.tec_ComM_BMSSOCHiErrSts_Enum
            REC_RTE_R_ComM_BMSSOCErrLoSts_Enum_tec_ComM_BMSSOCLoErrSts_Enum: accessed-variable=RTE_R_ComM_BMSSOCErrLoSts_Enum.tec_ComM_BMSSOCLoErrSts_Enum
            REC_RTE_R_ComM_BMSSts01ErrInfo_Bus_tec_ComM_BMSSts01TimeoutInfo_Bus: accessed-variable=RTE_R_ComM_BMSSts01ErrInfo_Bus.tec_ComM_BMSSts01TimeoutInfo_Bus
            REC_RTE_R_ComM_CANBusOffInfo_Bus_tec_ComM_EPTCANBusOffInfo_Bus: accessed-variable=RTE_R_ComM_CANBusOffInfo_Bus.tec_ComM_EPTCANBusOffInfo_Bus
            REC_RTE_R_ComM_CMLMaxOutpIDc_A_tec_ComM_CMLMaxOutpIDc_A: accessed-variable=RTE_R_ComM_CMLMaxOutpIDc_A.tec_ComM_CMLMaxOutpIDc_A
            REC_RTE_R_ComM_CMLMaxOutpUDc_V_tec_ComM_CMLMaxOutpUDc_V: accessed-variable=RTE_R_ComM_CMLMaxOutpUDc_V.tec_ComM_CMLMaxOutpUDc_V
            REC_RTE_R_ComM_CMLMinOutpIDc_A_tec_ComM_CMLMinOutpIDc_A: accessed-variable=RTE_R_ComM_CMLMinOutpIDc_A.tec_ComM_CMLMinOutpIDc_A
            REC_RTE_R_ComM_CMLMinOutpUDc_V_tec_ComM_CMLMinOutpUDc_V: accessed-variable=RTE_R_ComM_CMLMinOutpUDc_V.tec_ComM_CMLMinOutpUDc_V
            REC_RTE_R_ComM_ChrgnIDcErrSts_Enum_tec_ComM_ChrgnIDcErrSts_Enum: accessed-variable=RTE_R_ComM_ChrgnIDcErrSts_Enum.tec_ComM_ChrgnIDcErrSts_Enum
            REC_RTE_R_ComM_ChrgnRchSetVal_Enum_tec_ComM_ChrgnRchSetVal_Enum: accessed-variable=RTE_R_ComM_ChrgnRchSetVal_Enum.tec_ComM_ChrgnRchSetVal_Enum
            REC_RTE_R_ComM_ChrgnRchTarCellUDc_Enum_tec_ComM_ChrgnRchTarCellUDc_Enum: accessed-variable=RTE_R_ComM_ChrgnRchTarCellUDc_Enum.tec_ComM_ChrgnRchTarCellUDc_Enum
            REC_RTE_R_ComM_ChrgnRchTarTotUDc_Enum_tec_ComM_ChrgnRchTarTotUDc_Enum: accessed-variable=RTE_R_ComM_ChrgnRchTarTotUDc_Enum.tec_ComM_ChrgnRchTarTotUDc_Enum
            REC_RTE_R_ComM_DcInletASnsrSts_Enum_tec_ComM_DcInletASnsrSts_Enum: accessed-variable=RTE_R_ComM_DcInletASnsrSts_Enum.tec_ComM_DcInletASnsrSts_Enum
            REC_RTE_R_ComM_DcInletATemp_C_tec_ComM_DcInletATemp_C: accessed-variable=RTE_R_ComM_DcInletATemp_C.tec_ComM_DcInletATemp_C
            REC_RTE_R_ComM_DcInletBSnsrSts_Enum_tec_ComM_DcInletATemp_C: accessed-variable=RTE_R_ComM_DcInletBSnsrSts_Enum.tec_ComM_DcInletBSnsrSts_Enum
            REC_RTE_R_ComM_DcInletBTemp_C_tec_ComM_DcInletBTemp_C: accessed-variable=RTE_R_ComM_DcInletBTemp_C.tec_ComM_DcInletBTemp_C
            REC_RTE_R_ComM_MaxCellUDcErrSts_Enum_tec_ComM_MaxCellUDcErrSts_Enum: accessed-variable=RTE_R_ComM_MaxCellUDcErrSts_Enum.tec_ComM_MaxCellUDcErrSts_Enum
            REC_RTE_R_ComM_MinCellUDcErrSts_Enum_tec_ComM_MinCellUDcErrSts_Enum: accessed-variable=RTE_R_ComM_MinCellUDcErrSts_Enum.tec_ComM_MinCellUDcErrSts_Enum
            REC_RTE_R_ComM_PODDCFCUDc_V_tec_ComM_PODDCFCUDc_V: accessed-variable=RTE_R_ComM_PODDCFCUDc_V.tec_ComM_PODDCFCUDc_V
            REC_RTE_R_ComM_PODDcPosRlySts_Enum_tec_ComM_PODDcPosRlySts_Enum: accessed-variable=RTE_R_ComM_PODDcPosRlySts_Enum.tec_ComM_PODDcPosRlySts_Enum
            REC_RTE_R_ComM_PODSts01TimeoutInfo_Bus_tec_ComM_PODSts01TimeoutInfo_Bus: accessed-variable=RTE_R_ComM_PODSts01TimeoutInfo_Bus.tec_ComM_PODSts01TimeoutInfo_Bus
            REC_RTE_R_ComM_RxSts_Flg_tec_ComM_RxCCSSts_Flg: accessed-variable=RTE_R_ComM_RxSts_Flg.tec_ComM_RxCCSSts_Flg
            REC_RTE_R_ComM_RxSts_Flg_tec_ComM_RxCEMSts_Flg: accessed-variable=RTE_R_ComM_RxSts_Flg.tec_ComM_RxCEMSts_Flg
            REC_RTE_R_ComM_RxSts_Flg_tec_ComM_RxCHMSts_Flg: accessed-variable=RTE_R_ComM_RxSts_Flg.tec_ComM_RxCHMSts_Flg
            REC_RTE_R_ComM_RxSts_Flg_tec_ComM_RxCMLSts_Flg: accessed-variable=RTE_R_ComM_RxSts_Flg.tec_ComM_RxCMLSts_Flg
            REC_RTE_R_ComM_RxSts_Flg_tec_ComM_RxCRMSts_Flg: accessed-variable=RTE_R_ComM_RxSts_Flg.tec_ComM_RxCRMSts_Flg
            REC_RTE_R_ComM_RxSts_Flg_tec_ComM_RxCROSts_Flg: accessed-variable=RTE_R_ComM_RxSts_Flg.tec_ComM_RxCROSts_Flg
            REC_RTE_R_ComM_RxSts_Flg_tec_ComM_RxCSDSts_Flg: accessed-variable=RTE_R_ComM_RxSts_Flg.tec_ComM_RxCSDSts_Flg
            REC_RTE_R_ComM_RxSts_Flg_tec_ComM_RxCSTSts_Flg: accessed-variable=RTE_R_ComM_RxSts_Flg.tec_ComM_RxCSTSts_Flg
            REC_RTE_R_DCChrMgmt_DcChrgnSts_Enum_tec_DCChrMgmt_DcChrgnSts_Enum: accessed-variable=RTE_R_DCChrMgmt_DcChrgnSts_Enum.tec_DCChrMgmt_DcChrgnSts_Enum
            REC_RTE_R_DCChrMgmt_TxSts_Flg_tec_DCChrMgmt_TxBCLSts_Flg: accessed-variable=RTE_R_DCChrMgmt_TxSts_Flg.tec_DCChrMgmt_TxBCLSts_Flg
            REC_RTE_R_DCChrMgmt_TxSts_Flg_tec_DCChrMgmt_TxBCPSts_Flg: accessed-variable=RTE_R_DCChrMgmt_TxSts_Flg.tec_DCChrMgmt_TxBCPSts_Flg
            REC_RTE_R_DCChrMgmt_TxSts_Flg_tec_DCChrMgmt_TxBCSSts_Flg: accessed-variable=RTE_R_DCChrMgmt_TxSts_Flg.tec_DCChrMgmt_TxBCSSts_Flg
            REC_RTE_R_DCChrMgmt_TxSts_Flg_tec_DCChrMgmt_TxBEMSts_Flg: accessed-variable=RTE_R_DCChrMgmt_TxSts_Flg.tec_DCChrMgmt_TxBEMSts_Flg
            REC_RTE_R_DCChrMgmt_TxSts_Flg_tec_DCChrMgmt_TxBHMSts_Flg: accessed-variable=RTE_R_DCChrMgmt_TxSts_Flg.tec_DCChrMgmt_TxBHMSts_Flg
            REC_RTE_R_DCChrMgmt_TxSts_Flg_tec_DCChrMgmt_TxBRMSts_Flg: accessed-variable=RTE_R_DCChrMgmt_TxSts_Flg.tec_DCChrMgmt_TxBRMSts_Flg
            REC_RTE_R_DCChrMgmt_TxSts_Flg_tec_DCChrMgmt_TxBROSts_Flg: accessed-variable=RTE_R_DCChrMgmt_TxSts_Flg.tec_DCChrMgmt_TxBROSts_Flg
            REC_RTE_R_DCChrMgmt_TxSts_Flg_tec_DCChrMgmt_TxBSDSts_Flg: accessed-variable=RTE_R_DCChrMgmt_TxSts_Flg.tec_DCChrMgmt_TxBSDSts_Flg
            REC_RTE_R_DCChrMgmt_TxSts_Flg_tec_DCChrMgmt_TxBSMSts_Flg: accessed-variable=RTE_R_DCChrMgmt_TxSts_Flg.tec_DCChrMgmt_TxBSMSts_Flg
            REC_RTE_R_DCChrMgmt_TxSts_Flg_tec_DCChrMgmt_TxBSTSts_Flg: accessed-variable=RTE_R_DCChrMgmt_TxSts_Flg.tec_DCChrMgmt_TxBSTSts_Flg
            REC_RTE_R_ErrMgmt_VCUHVILErr_Flg_tec_ErrMgmt_VCUHVILErr_Flg: accessed-variable=RTE_R_ErrMgmt_VCUHVILErr_Flg.tec_ErrMgmt_VCUHVILErr_Flg
            REC_RTE_R_IOAbs_CC2SigUDc_mV_tec_IOAbs_CC2SigUDc_mV: accessed-variable=RTE_R_IOAbs_CC2SigUDc_mV.tec_IOAbs_CC2SigUDc_mV
            REC_RTE_R_LvMgmt_BSBattUDcNorm_Flg_tec_LvMgmt_BSBattUDcNorm_Flg: accessed-variable=RTE_R_LvMgmt_BSBattUDcNorm_Flg.tec_LvMgmt_BSBattUDcNorm_Flg
            REC_RTE_R_DCChrMgmt_BROPrepFinshd_Enum_tec_DCChrMgmt_BROPrepFinshd_Enum: accessed-variable=RTE_R_DCChrMgmt_BROPrepFinshd_Enum.tec_DCChrMgmt_BROPrepFinshd_Enum
            REC_RTE_R_DiagApp_DisableDCMReqInfo_tec_DiagApp_DisableDCMReqInfo: accessed-variable=RTE_R_DiagApp_DisableDCMReqInfo.tec_DiagApp_DisableDCMReqInfo
            REC_RTE_R_ComM_CANBusOffInfo_Bus_tec_ComM_DCCANBusOffInfo_Bus: accessed-variable=RTE_R_ComM_CANBusOffInfo_Bus.tec_ComM_DCCANBusOffInfo_Bus
        data-send-points:
          51 x access:
            SEND_RTE_P_DCChrMgmt_BEMRxCCSTmtDTC_Bus_tec_DCChrMgmt_BEMRxCCSTmtDTC_Bus: accessed-variable=RTE_P_DCChrMgmt_BEMRxCCSTmtDTC_Bus.tec_DCChrMgmt_BEMRxCCSTmtDTC_Bus
            SEND_RTE_P_DCChrMgmt_BEMRxCCSTmt_Bus_tec_DCChrMgmt_BEMRxCCSTmt_Bus: accessed-variable=RTE_P_DCChrMgmt_BEMRxCCSTmt_Bus.tec_DCChrMgmt_BEMRxCCSTmt_Bus
            SEND_RTE_P_DCChrMgmt_BEMRxCMLTmtDTC_Bus_tec_DCChrMgmt_BEMRxCMLTmtDTC_Bus: accessed-variable=RTE_P_DCChrMgmt_BEMRxCMLTmtDTC_Bus.tec_DCChrMgmt_BEMRxCMLTmtDTC_Bus
            SEND_RTE_P_DCChrMgmt_BEMRxCMLTmt_Bus_tec_DCChrMgmt_BEMRxCMLTmt_Bus: accessed-variable=RTE_P_DCChrMgmt_BEMRxCMLTmt_Bus.tec_DCChrMgmt_BEMRxCMLTmt_Bus
            SEND_RTE_P_DCChrMgmt_BEMRxCRMPrepdTmtDTC_Bus_tec_DCChrMgmt_BEMRxCRMPrepdTmtDTC_Bus: accessed-variable=RTE_P_DCChrMgmt_BEMRxCRMPrepdTmtDTC_Bus.tec_DCChrMgmt_BEMRxCRMPrepdTmtDTC_Bus
            SEND_RTE_P_DCChrMgmt_BEMRxCRMPrepdTmt_Bus_tec_DCChrMgmt_BEMRxCRMPrepdTmt_Bus: accessed-variable=RTE_P_DCChrMgmt_BEMRxCRMPrepdTmt_Bus.tec_DCChrMgmt_BEMRxCRMPrepdTmt_Bus
            SEND_RTE_P_DCChrMgmt_BEMRxCRMTmtDTC_Bus_tec_DCChrMgmt_BEMRxCRMTmtDTC_Bus: accessed-variable=RTE_P_DCChrMgmt_BEMRxCRMTmtDTC_Bus.tec_DCChrMgmt_BEMRxCRMTmtDTC_Bus
            SEND_RTE_P_DCChrMgmt_BEMRxCRMTmt_Bus_tec_DCChrMgmt_BEMRxCRMTmt_Bus: accessed-variable=RTE_P_DCChrMgmt_BEMRxCRMTmt_Bus.tec_DCChrMgmt_BEMRxCRMTmt_Bus
            SEND_RTE_P_DCChrMgmt_BEMRxCROPrepdTmtDTC_Bus_tec_DCChrMgmt_BEMRxCROPrepdTmtDTC_Bus: accessed-variable=RTE_P_DCChrMgmt_BEMRxCROPrepdTmtDTC_Bus.tec_DCChrMgmt_BEMRxCROPrepdTmtDTC_Bus
            SEND_RTE_P_DCChrMgmt_BEMRxCROPrepdTmt_Bus_tec_DCChrMgmt_BEMRxCROPrepdTmt_Bus: accessed-variable=RTE_P_DCChrMgmt_BEMRxCROPrepdTmt_Bus.tec_DCChrMgmt_BEMRxCROPrepdTmt_Bus
            SEND_RTE_P_DCChrMgmt_BEMRxCROTmtDTC_Bus_tec_DCChrMgmt_BEMRxCROTmtDTC_Bus: accessed-variable=RTE_P_DCChrMgmt_BEMRxCROTmtDTC_Bus.tec_DCChrMgmt_BEMRxCROTmtDTC_Bus
            SEND_RTE_P_DCChrMgmt_BEMRxCROTmt_Bus_tec_DCChrMgmt_BEMRxCROTmt_Bus: accessed-variable=RTE_P_DCChrMgmt_BEMRxCROTmt_Bus.tec_DCChrMgmt_BEMRxCROTmt_Bus
            SEND_RTE_P_DCChrMgmt_BEMRxCSDTmtDTC_Bus_tec_DCChrMgmt_BEMRxCSDTmtDTC_Bus: accessed-variable=RTE_P_DCChrMgmt_BEMRxCSDTmtDTC_Bus.tec_DCChrMgmt_BEMRxCSDTmtDTC_Bus
            SEND_RTE_P_DCChrMgmt_BEMRxCSDTmt_Bus_tec_DCChrMgmt_BEMRxCSDTmt_Bu: accessed-variable=RTE_P_DCChrMgmt_BEMRxCSDTmt_Bus.tec_DCChrMgmt_BEMRxCSDTmt_Bus
            SEND_RTE_P_DCChrMgmt_BEMRxCSTTmtDTC_Bus_tec_DCChrMgmt_BEMRxCSTTmtDTC_Bus: accessed-variable=RTE_P_DCChrMgmt_BEMRxCSTTmtDTC_Bus.tec_DCChrMgmt_BEMRxCSTTmtDTC_Bus
            SEND_RTE_P_DCChrMgmt_BEMRxCSTTmt_Bus_tec_DCChrMgmt_BEMRxCSTTmt_Bus: accessed-variable=RTE_P_DCChrMgmt_BEMRxCSTTmt_Bus.tec_DCChrMgmt_BEMRxCSTTmt_Bus
            SEND_RTE_P_DCChrMgmt_BEMTxReqSts_Enum_tec_DCChrMgmt_BEMTxReqSts_Enum: accessed-variable=RTE_P_DCChrMgmt_BEMTxReqSts_Enum.tec_DCChrMgmt_BEMTxReqSts_Enum
            SEND_RTE_P_DCChrMgmt_BSMBattTempHiErrSts_Enum_tec_DCChrMgmt_BSMBattTempHiErrSts_Enum: accessed-variable=RTE_P_DCChrMgmt_BSMBattTempHiErrSts_Enum.tec_DCChrMgmt_BSMBattTempHiErrSts_Enum
            SEND_RTE_P_DCChrMgmt_BSMCellUDcErrSts_Enum_tec_DCChrMgmt_BSMCellUDcErrSts_Enum: accessed-variable=RTE_P_DCChrMgmt_BSMCellUDcErrSts_Enum.tec_DCChrMgmt_BSMCellUDcErrSts_Enum
            SEND_RTE_P_DCChrMgmt_BSMChrgAllwbl_Flg_tec_DCChrMgmt_BSMChrgAllwbl_Flg: accessed-variable=RTE_P_DCChrMgmt_BSMChrgAllwbl_Flg.tec_DCChrMgmt_BSMChrgAllwbl_Flg
            SEND_RTE_P_DCChrMgmt_BSMChrgnIDcErrSts_Enum_tec_DCChrMgmt_BSMChrgnIDcErrSts_Enum: accessed-variable=RTE_P_DCChrMgmt_BSMChrgnIDcErrSts_Enum.tec_DCChrMgmt_BSMChrgnIDcErrSts_Enum
            SEND_RTE_P_DCChrMgmt_BSMIRErrSts_Enum_tec_DCChrMgmt_BSMIRErrSts_Enum: accessed-variable=RTE_P_DCChrMgmt_BSMIRErrSts_Enum.tec_DCChrMgmt_BSMIRErrSts_Enum
            SEND_RTE_P_DCChrMgmt_BSMOutpCnctErrSts_Enum_tec_DCChrMgmt_BSMOutpCnctErrSts_Enum: accessed-variable=RTE_P_DCChrMgmt_BSMOutpCnctErrSts_Enum.tec_DCChrMgmt_BSMOutpCnctErrSts_Enum
            SEND_RTE_P_DCChrMgmt_BSMSOCErrSts_Enum_tec_DCChrMgmt_BSMSOCErrSts_Enum: accessed-variable=RTE_P_DCChrMgmt_BSMSOCErrSts_Enum.tec_DCChrMgmt_BSMSOCErrSts_Enum
            SEND_RTE_P_DCChrMgmt_BSTBMSCnctOvrTemp_Enum_tec_DCChrMgmt_BSTBMSCnctOvrTemp_Enum: accessed-variable=RTE_P_DCChrMgmt_BSTBMSCnctOvrTemp_Enum.tec_DCChrMgmt_BSTBMSCnctOvrTemp_Enum
            SEND_RTE_P_DCChrMgmt_BSTBattOvrTempErr_Enum_tec_DCChrMgmt_BSTBattOvrTempErr_Enum: accessed-variable=RTE_P_DCChrMgmt_BSTBattOvrTempErr_Enum.tec_DCChrMgmt_BSTBattOvrTempErr_Enum
            SEND_RTE_P_DCChrMgmt_BSTChkCC2UDcErr_Enum_tec_DCChrMgmt_BSTChkCC2UDcErr_Enum: accessed-variable=RTE_P_DCChrMgmt_BSTChkCC2UDcErr_Enum.tec_DCChrMgmt_BSTChkCC2UDcErr_Enum
            SEND_RTE_P_DCChrMgmt_BSTChrgCnctErrSts_Enum_tec_DCChrMgmt_BSTChrgCnctErrSts_Enum: accessed-variable=RTE_P_DCChrMgmt_BSTChrgCnctErrSts_Enum.tec_DCChrMgmt_BSTChrgCnctErrSts_Enum
            SEND_RTE_P_DCChrMgmt_BSTChrgPrmErr_Enum_tec_DCChrMgmt_BSTChrgPrmErr_Enum: accessed-variable=RTE_P_DCChrMgmt_BSTChrgPrmErr_Enum.tec_DCChrMgmt_BSTChrgPrmErr_Enum
            SEND_RTE_P_DCChrMgmt_BSTChrgrStopSts_Enum_tec_DCChrMgmt_BSTChrgrStopSts_Enum: accessed-variable=RTE_P_DCChrMgmt_BSTChrgrStopSts_Enum.tec_DCChrMgmt_BSTChrgrStopSts_Enum
            SEND_RTE_P_DCChrMgmt_BSTHvRlyErrSts_Enum_tec_DCChrMgmt_BSTHvRlyErrSts_Enum: accessed-variable=RTE_P_DCChrMgmt_BSTHvRlyErrSts_Enum.tec_DCChrMgmt_BSTHvRlyErrSts_Enum
            SEND_RTE_P_DCChrMgmt_BSTIDcErrSts_Enum_tec_DCChrMgmt_BSTIDcErrSts_Enum: accessed-variable=RTE_P_DCChrMgmt_BSTIDcErrSts_Enum.tec_DCChrMgmt_BSTIDcErrSts_Enum
            SEND_RTE_P_DCChrMgmt_BSTIRErrStopSts_Enum_tec_DCChrMgmt_BSTIRErrStopSts_Enum: accessed-variable=RTE_P_DCChrMgmt_BSTIRErrStopSts_Enum.tec_DCChrMgmt_BSTIRErrStopSts_Enum
            SEND_RTE_P_DCChrMgmt_BSTOtherErr_Enum_tec_DCChrMgmt_BSTOtherErr_Enum: accessed-variable=RTE_P_DCChrMgmt_BSTOtherErr_Enum.tec_DCChrMgmt_BSTOtherErr_Enum
            SEND_RTE_P_DCChrMgmt_BSTOutpCnctOvrTemp_Enum_tec_DCChrMgmt_BSTOutpCnctOvrTemp_Enum: accessed-variable=RTE_P_DCChrMgmt_BSTOutpCnctOvrTemp_Enum.tec_DCChrMgmt_BSTOutpCnctOvrTemp_Enum
            SEND_RTE_P_DCChrMgmt_BSTRchTarCellUDc_Enum_tec_DCChrMgmt_BSTRchTarCellUDc_Enum: accessed-variable=RTE_P_DCChrMgmt_BSTRchTarCellUDc_Enum.tec_DCChrMgmt_BSTRchTarCellUDc_Enum
            SEND_RTE_P_DCChrMgmt_BSTRchTarSOC_Enum_tec_DCChrMgmt_BSTRchTarSOC_Enum: accessed-variable=RTE_P_DCChrMgmt_BSTRchTarSOC_Enum.tec_DCChrMgmt_BSTRchTarSOC_Enum
            SEND_RTE_P_DCChrMgmt_BSTRchTarTotUDc_Enum_tec_DCChrMgmt_BSTRchTarTotUDc_Enum: accessed-variable=RTE_P_DCChrMgmt_BSTRchTarTotUDc_Enum.tec_DCChrMgmt_BSTRchTarTotUDc_Enum
            SEND_RTE_P_DCChrMgmt_BSTUDcErrSts_Enum_tec_DCChrMgmt_BSTUDcErrSts_Enum: accessed-variable=RTE_P_DCChrMgmt_BSTUDcErrSts_Enum.tec_DCChrMgmt_BSTUDcErrSts_Enum
            SEND_RTE_P_DCChrMgmt_DcChrgrCpbyPassd_Flg_tec_DCChrMgmt_DcChrgrCpbyPassd_Flg: accessed-variable=RTE_P_DCChrMgmt_DcChrgrCpbyPassd_Flg.tec_DCChrMgmt_DcChrgrCpbyPassd_Flg
            SEND_RTE_P_DCChrMgmt_DcPortTempErrLvl1DTC_Bus_tec_DCChrMgmt_DcPortTempErrLvl1DTC_Bus: accessed-variable=RTE_P_DCChrMgmt_DcPortTempErrLvl1DTC_Bus.tec_DCChrMgmt_DcPortTempErrLvl1DTC_Bus
            SEND_RTE_P_DCChrMgmt_DcPortTempErrLvl1_Bus_tec_DCChrMgmt_DcPortTempErrLvl1_Bus: accessed-variable=RTE_P_DCChrMgmt_DcPortTempErrLvl1_Bus.tec_DCChrMgmt_DcPortTempErrLvl1_Bus
            SEND_RTE_P_DCChrMgmt_DcPortTempErrLvl2DTC_Bus_tec_DCChrMgmt_DcPortTempErrLvl2DTC_Bus: accessed-variable=RTE_P_DCChrMgmt_DcPortTempErrLvl2DTC_Bus.tec_DCChrMgmt_DcPortTempErrLvl2DTC_Bus
            SEND_RTE_P_DCChrMgmt_DcPortTempErrLvl2_Bus_tec_DCChrMgmt_DcPortTempErrLvl2_Bus: accessed-variable=RTE_P_DCChrMgmt_DcPortTempErrLvl2_Bus.tec_DCChrMgmt_DcPortTempErrLvl2_Bus
            SEND_RTE_P_DCChrMgmt_DcPortTempSnsrErrDTC_Bus_tec_DCChrMgmt_DcPortTempSnsrErrDTC_Bus: accessed-variable=RTE_P_DCChrMgmt_DcPortTempSnsrErrDTC_Bus.tec_DCChrMgmt_DcPortTempSnsrErrDTC_Bus
            SEND_RTE_P_DCChrMgmt_DcPortTempSnsrErr_Bus_tec_DCChrMgmt_DcPortTempSnsrErr_Bus: accessed-variable=RTE_P_DCChrMgmt_DcPortTempSnsrErr_Bus.tec_DCChrMgmt_DcPortTempSnsrErr_Bus
            SEND_RTE_P_DCChrMgmt_MaxChrgIDc_A_tec_DCChrMgmt_MaxChrgIDc_A: accessed-variable=RTE_P_DCChrMgmt_MaxChrgIDc_A.tec_DCChrMgmt_MaxChrgIDc_A
            SEND_RTE_P_DCChrMgmt_MaxChrgUDc_V_tec_DCChrMgmt_MaxChrgUDc_V: accessed-variable=RTE_P_DCChrMgmt_MaxChrgUDc_V.tec_DCChrMgmt_MaxChrgUDc_V
            SEND_RTE_P_DCChrMgmt_MinChrgIDc_A_tec_DCChrMgmt_MinChrgIDc_A: accessed-variable=RTE_P_DCChrMgmt_MinChrgIDc_A.tec_DCChrMgmt_MinChrgIDc_A
            SEND_RTE_P_DCChrMgmt_MinChrgUDc_V_tec_DCChrMgmt_MinChrgUDc_V: accessed-variable=RTE_P_DCChrMgmt_MinChrgUDc_V.tec_DCChrMgmt_MinChrgUDc_V
            SEND_RTE_P_DCChrMgmt_BSTTxReqSts_tec_DCChrMgmt_BSTTxReqSts: accessed-variable=RTE_P_DCChrMgmt_BSTTxReqSts.tec_DCChrMgmt_BSTTxReqSts
      runnable R_ChrgComM_Init
  swc implementation CtAp_ChrgComM_Implementation: behavior=CtAp_ChrgComM_InternalBehavior
